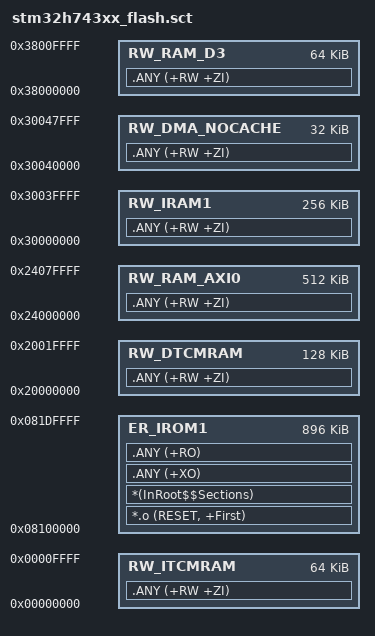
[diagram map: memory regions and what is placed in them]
; *********************************************************************************
; *** Scatter-Loading Description File generated by STM32CubeMX/LinkerGenerator ***
; *********************************************************************************;

LR_IROM1 0x08100000 0x000E0000  {  ; load_region size_region
  ER_IROM1 0x08100000 0x000E0000  {  ; load address = excetion address
   *.o (RESET, +First)
   *(InRoot$$Sections)
   .ANY (+XO)
   .ANY (+RO)
  }
  RW_IRAM1 0x30000000 0x00040000  {  ; load address = excetion address
   .ANY (+RW +ZI)
  }
;***region***;

  RW_DTCMRAM 0x20000000 0x00020000  {  ; load address = excetion address
   .ANY (+RW +ZI)
  }

  RW_RAM_AXI0 0x24000000 0x00080000  {  ; load address = excetion address
   .ANY (+RW +ZI)
  }

  RW_RAM_D3 0x38000000 0x00010000  {  ; load address = excetion address
   .ANY (+RW +ZI)
  }

  RW_ITCMRAM 0x00000000 0x00010000  {  ; load address = excetion address
   .ANY (+RW +ZI)
  }

  RW_DMA_NOCACHE 0x30040000 0x00008000  {  ; load address = excetion address
   .ANY (+RW +ZI)
  }
;***endregion***;
}


/*-Start of  regions- Auto-generated By STM32CubeMX-*/


